# AT91SAM9G20 register map
Vendor: Atmel; File version: 20130207
CPU: 
Registers are 32-bit, read-write, reset 0x0 unless marked. A register's access mark holds for its fields unless they carry their own. Offsets are from the block's base; [hi:lo] are bit positions; {n}, {i} and the like mark numbered series; 'fields as' and 'values as' point back to an identical list.

## PMC — Power Management Controller
Base 0xFFFFFC00
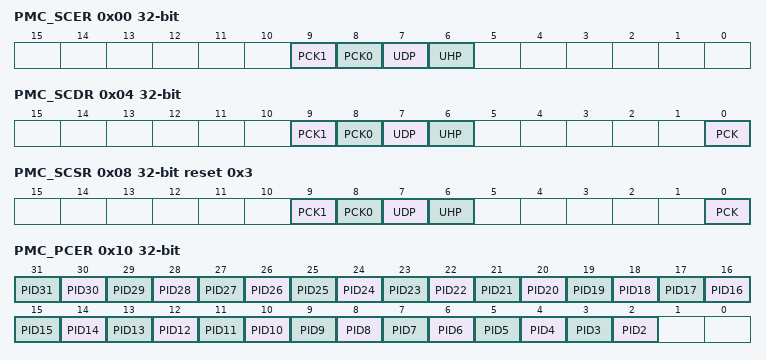
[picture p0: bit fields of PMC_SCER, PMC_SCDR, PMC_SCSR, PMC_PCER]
0x00 PMC_SCER wo reset not defined — System Clock Enable Register
  [9] PCK1 — Programmable Clock 1 Output Enable
  [8] PCK0 — Programmable Clock 0 Output Enable
  [7] UDP — USB Device Port Clock Enable
  [6] UHP — USB Host Port Clock Enable
0x04 PMC_SCDR wo reset not defined — System Clock Disable Register
  [9] PCK1 — Programmable Clock 1 Output Disable
  [8] PCK0 — Programmable Clock 0 Output Disable
  [7] UDP — USB Device Port Clock Disable
  [6] UHP — USB Host Port Clock Disable
  [0] PCK — Processor Clock Disable
0x08 PMC_SCSR ro reset 0x3 — System Clock Status Register
  [9] PCK1 — Programmable Clock 1 Output Status
  [8] PCK0 — Programmable Clock 0 Output Status
  [7] UDP — USB Device Port Clock Status
  [6] UHP — USB Host Port Clock Status
  [0] PCK — Processor Clock Status
0x10 PMC_PCER wo reset not defined — Peripheral Clock Enable Register
  [n] PID{n} (n=2..31) — Peripheral Clock {n} Enable
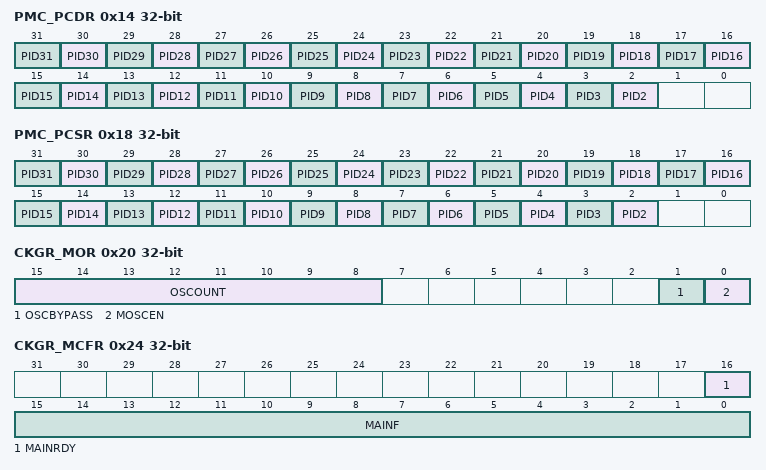
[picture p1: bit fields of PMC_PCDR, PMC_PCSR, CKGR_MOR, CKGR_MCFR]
0x14 PMC_PCDR wo reset not defined — Peripheral Clock Disable Register
  [n] PID{n} (n=2..31) — Peripheral Clock {n} Disable
0x18 PMC_PCSR ro — Peripheral Clock Status Register
  [n] PID{n} (n=2..31) — Peripheral Clock {n} Status
0x20 CKGR_MOR — Main Oscillator Register
  [15:8] OSCOUNT — Main Oscillator Start-up Time
  [1] OSCBYPASS — Oscillator Bypass
  [0] MOSCEN — Main Oscillator Enable
0x24 CKGR_MCFR ro — Main Clock Frequency Register
  [16] MAINRDY — Main Clock Ready
  [15:0] MAINF — Main Clock Frequency
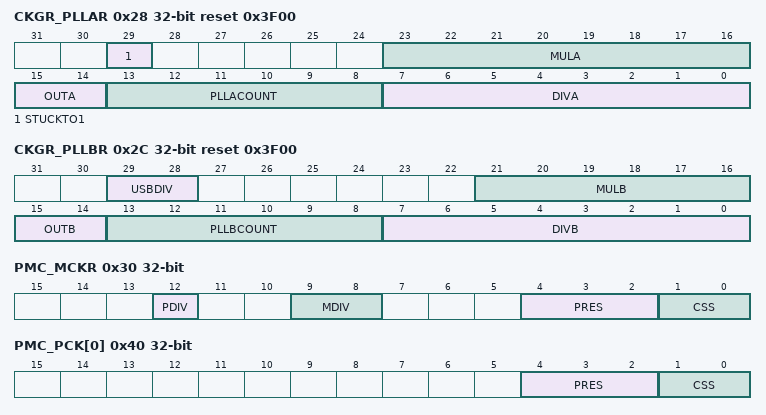
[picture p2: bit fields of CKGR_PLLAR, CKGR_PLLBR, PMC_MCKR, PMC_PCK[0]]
0x28 CKGR_PLLAR reset 0x3F00 — PLL A Register
  [29] STUCKTO1
  [23:16] MULA — PLL A Multiplier
  [15:14] OUTA — PLL A Clock Frequency Range
  [13:8] PLLACOUNT — PLL A Counter
  [7:0] DIVA — Divider A
0x2C CKGR_PLLBR reset 0x3F00 — PLL B Register
  [29:28] USBDIV — Divider for USB Clock.
  [21:16] MULB — PLL B Multiplier
  [15:14] OUTB — PLL B Clock Frequency Range
  [13:8] PLLBCOUNT — PLL B Counter
  [7:0] DIVB — Divider B
0x30 PMC_MCKR — Master Clock Register
  [12] PDIV — Processor Clock Division
  [9:8] MDIV — Master Clock Division
  [4:2] PRES — Master/Processor Clock Prescaler
  [1:0] CSS — Master/Processor Clock Source Selection
0x40 PMC_PCK[0] reset not defined — Programmable Clock 0 Register
  [4:2] PRES — Programmable Clock Prescaler
  [1:0] CSS — Master Clock Selection
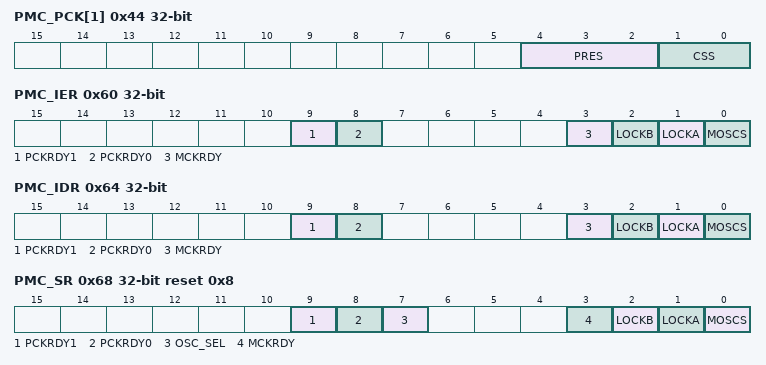
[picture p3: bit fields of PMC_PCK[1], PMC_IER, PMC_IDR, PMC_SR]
0x44 PMC_PCK[1] reset not defined — Programmable Clock 0 Register
  fields as PMC_PCK[0]
0x60 PMC_IER wo reset not defined — Interrupt Enable Register
  [9] PCKRDY1 — Programmable Clock Ready 1 Interrupt Enable
  [8] PCKRDY0 — Programmable Clock Ready 0 Interrupt Enable
  [3] MCKRDY — Master Clock Ready Interrupt Enable
  [2] LOCKB — PLL B Lock Interrupt Enable
  [1] LOCKA — PLL A Lock Interrupt Enable
  [0] MOSCS — Main Oscillator Status Interrupt Enable
0x64 PMC_IDR wo reset not defined — Interrupt Disable Register
  [9] PCKRDY1 — Programmable Clock Ready 1 Interrupt Disable
  [8] PCKRDY0 — Programmable Clock Ready 0 Interrupt Disable
  [3] MCKRDY — Master Clock Ready Interrupt Disable
  [2] LOCKB — PLL B Lock Interrupt Disable
  [1] LOCKA — PLL A Lock Interrupt Disable
  [0] MOSCS — Main Oscillator Status Interrupt Disable
0x68 PMC_SR ro reset 0x8 — Status Register
  [9] PCKRDY1 — Programmable Clock Ready Status
  [8] PCKRDY0 — Programmable Clock Ready Status
  [7] OSC_SEL — Slow Clock Oscillator Selection
  [3] MCKRDY — Master Clock Status
  [2] LOCKB — PLL B Lock Status
  [1] LOCKA — PLL A Lock Status
  [0] MOSCS — Main Oscillator Status
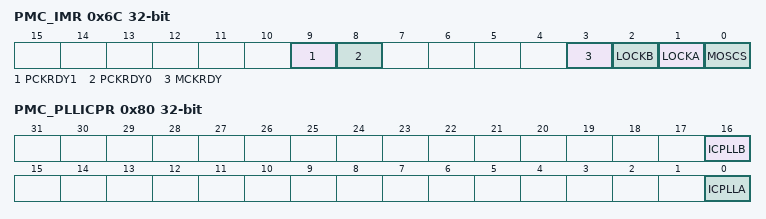
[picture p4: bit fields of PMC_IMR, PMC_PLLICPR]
0x6C PMC_IMR ro — Interrupt Mask Register
  [9] PCKRDY1 — Programmable Clock Ready Interrupt Mask
  [8] PCKRDY0 — Programmable Clock Ready Interrupt Mask
  [3] MCKRDY — Master Clock Ready Interrupt Mask
  [2] LOCKB — PLL B Lock Interrupt Mask
  [1] LOCKA — PLL A Lock Interrupt Mask
  [0] MOSCS — Main Oscillator Status Interrupt Mask
0x80 PMC_PLLICPR wo — PLL Charge Pump Current Register
  [16] ICPLLB — Charge Pump Current
  [0] ICPLLA — Charge Pump Current
